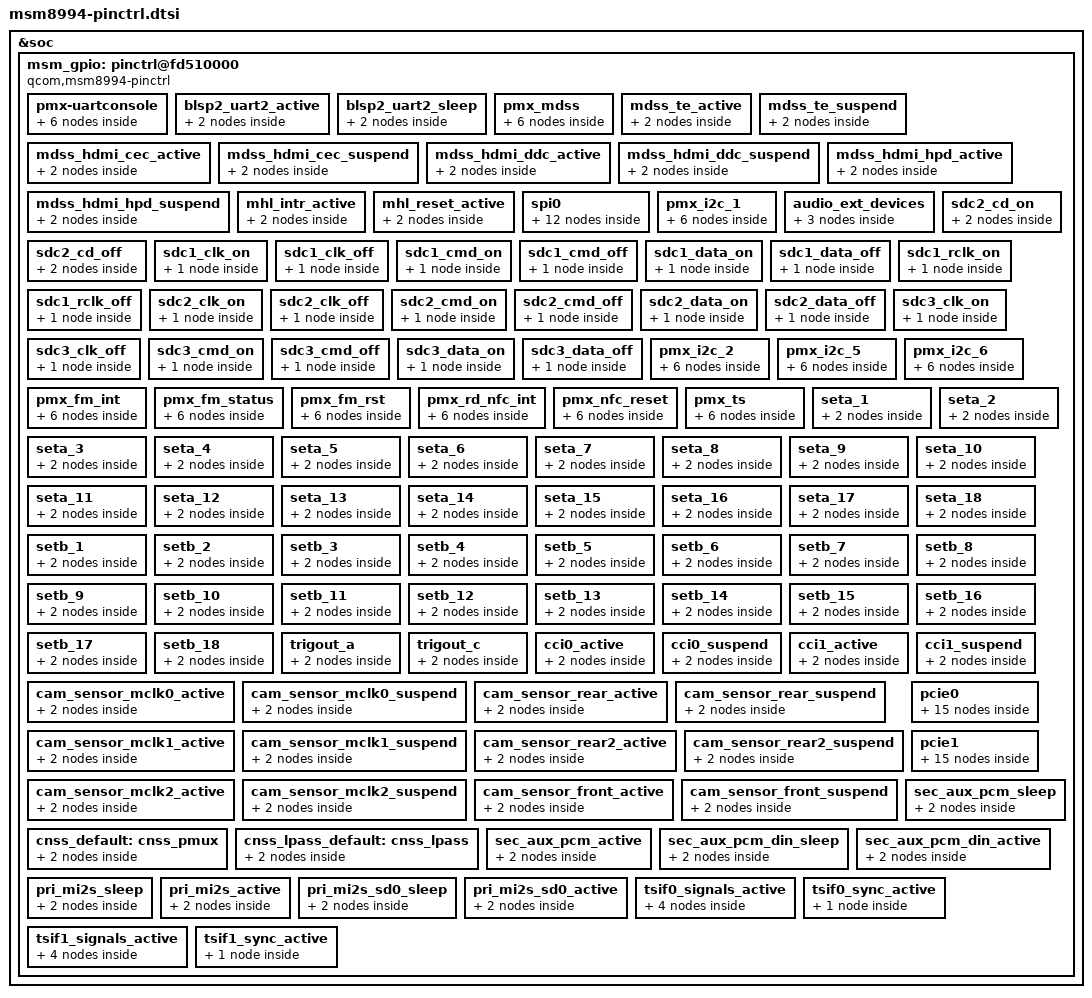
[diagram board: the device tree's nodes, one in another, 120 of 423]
/* Copyright (c) 2013-2015, The Linux Foundation. All rights reserved.
 * Copyright (C) 2016, AngeloGioacchino Del Regno <kholk11@gmail.com>
 *
 * This program is free software; you can redistribute it and/or modify
 * it under the terms of the GNU General Public License version 2 and
 * only version 2 as published by the Free Software Foundation.
 *
 * This program is distributed in the hope that it will be useful,
 * but WITHOUT ANY WARRANTY; without even the implied warranty of
 * MERCHANTABILITY or FITNESS FOR A PARTICULAR PURPOSE.  See the
 * GNU General Public License for more details.
 */

&soc {
	msm_gpio: pinctrl@fd510000 {
		compatible = "qcom,msm8994-pinctrl";
		reg = <0xfd510000 0x4000>;
		interrupts = <0 208 0>;
		gpio-controller;
		#gpio-cells = <2>;
		interrupt-controller;
		#interrupt-cells = <2>;

		pmx-uartconsole {
			uart_console_active: uart_console_active {
				mux {
					pins = "gpio4", "gpio5";
					function = "blsp_uart2";
				};

				config {
					pins = "gpio4", "gpio5";
					drive-strength = <2>;
					bias-disable;
				};
			};

			uart_console_sleep: uart_console_sleep {
				mux {
					pins = "gpio4", "gpio5";
					function = "blsp_uart2";
				};

				config {
					pins = "gpio4", "gpio5";
					drive-strength = <2>;
					bias-pull-down;
				};
			};
		};

		blsp2_uart2_active: blsp2_uart2_active {
			mux {
				pins = "gpio45", "gpio46", "gpio47", "gpio48";
				function = "blsp_uart8";
			};

			config {
				pins = "gpio45", "gpio46", "gpio47", "gpio48";
				drive-strength = <16>;
				bias-disable;
			};
		};

		blsp2_uart2_sleep: blsp2_uart2_sleep {
			mux {
				pins = "gpio45", "gpio46", "gpio47", "gpio48";
				function = "gpio";
			};

			config {
				pins = "gpio45", "gpio46", "gpio47", "gpio48";
				drive-strength = <2>;
				bias-disable;
			};
		};

		pmx_mdss: pmx_mdss {
			mdss_dsi_active: mdss_dsi_active {
				mux {
					pins = "gpio78";
					function = "gpio";
				};

				config {
					pins = "gpio78";
					drive-strength = <8>; /* 8 mA */
					bias-disable = <0>; /* no pull */
				};
			};
			mdss_dsi_suspend: mdss_dsi_suspend {
				mux {
					pins = "gpio78";
					function = "gpio";
				};

				config {
					pins = "gpio78";
					drive-strength = <2>; /* 2 mA */
					bias-pull-down; /* pull down */
				};
			};
		};

		mdss_te_active: mdss_te_active {
			mux {
				pins = "gpio10";
				function = "mdp_vsync";
			};
			config {
				pins = "gpio10";
				drive-strength = <2>; /* 8 mA */
				bias-pull-down; /* pull down*/
			};
		};


		mdss_te_suspend: mdss_te_suspend {
			mux {
				pins = "gpio10";
				function = "mdp_vsync";
			};
			config {
				pins = "gpio10";
				drive-strength = <2>; /* 2 mA */
				bias-pull-down; /* pull down */
			};
		};

		mdss_hdmi_cec_active: mdss_hdmi_cec_active {
			mux {
				pins = "gpio31";
				function = "hdmi_cec";
			};

			config {
				pins = "gpio31";
				drive-strength = <2>;
				bias-pull-up;
			};
		};

		mdss_hdmi_cec_suspend: mdss_hdmi_cec_suspend {
			mux {
				pins = "gpio31";
				function = "hdmi_cec";
			};

			config {
				pins = "gpio31";
				drive-strength = <2>;
				bias-pull-up;
			};
		};

		mdss_hdmi_ddc_active: mdss_hdmi_ddc_active {
			mux {
				pins = "gpio32", "gpio33";
				function = "hdmi_ddc";
			};

			config {
				pins = "gpio32", "gpio33";
				drive-strength = <2>;
				bias-pull-up;
			};
		};

		mdss_hdmi_ddc_suspend: mdss_hdmi_ddc_suspend {
			mux {
				pins = "gpio32", "gpio33";
				function = "hdmi_ddc";
			};

			config {
				pins = "gpio32", "gpio33";
				drive-strength = <2>;
				bias-pull-down;
			};
		};

		mdss_hdmi_hpd_active: mdss_hdmi_hpd_active {
			mux {
				pins = "gpio34";
				function = "hdmi_hpd";
			};

			config {
				pins = "gpio34";
				bias-pull-down;
				drive-strength = <16>;
			};
		};

		mdss_hdmi_hpd_suspend: mdss_hdmi_hpd_suspend {
			mux {
				pins = "gpio34";
				function = "hdmi_hpd";
			};

			config {
				pins = "gpio34";
				bias-pull-down;
				drive-strength = <2>;
			};
		};

		mhl_intr_active: mhl_intr_active {
			mux {
				pins = "gpio57";
				function = "gpio";
			};

			config {
				pins = "gpio57";
				bias-pull-up;
				input-enable;
			};
		};

		mhl_reset_active: mhl_reset_active {
			mux {
				pins = "gpio58";
				function = "gpio";
			};

			config {
				pins = "gpio58";
				drive-strength = <2>;
				bias-pull-down;
				output-low;
			};
		};

		spi0 {

			spi0_default: spi0_default {
				/* active state */
				mux {
					/* MOSI, MISO, CLK */
					pins = "gpio0", "gpio1", "gpio3";
					function = "blsp_spi1";
				};

				config {
					pins = "gpio0", "gpio1", "gpio3";
					drive-strength = <12>; /* 12 MA */
					bias-disable = <0>; /* No PULL */
				};
			};


			spi0_sleep: spi0_sleep {
				/* suspended state */
				mux {
					/* MOSI, MISO, CLK */
					pins = "gpio0", "gpio1", "gpio3";
					function = "gpio";
				};

				config {
					pins = "gpio0", "gpio1", "gpio3";
					drive-strength = <2>; /* 2 MA */
					bias-pull-down; /* PULL Down */
				};
			};

			spi0_cs1_active: cs1_active {
				/* CS */
				mux {
					pins = "gpio8";
					function = "blsp_spi1_cs1";
				};

				config {
					pins = "gpio8";
					drive-strength = <2>;
					bias-disable = <0>;
				};
			};

			spi0_cs1_sleep: cs1_sleep {
				/* CS */
				mux {
					pins = "gpio8";
					function = "gpio";
				};

				config {
					pins = "gpio8";
					drive-strength = <2>;
					bias-disable = <0>;
				};
			};
		};

		pmx_i2c_1 {
			/* active state */
			i2c_1_active: i2c_1_active{
				mux {
					/* CLK, DATA */
					pins = "gpio2", "gpio3";
					function = "blsp_i2c1";
				};

				config {
					pins = "gpio2", "gpio3";
					drive-strength = <2>; /* 2 MA */
					bias-disable; /* No PULL */
				};
			};

			/* suspended state */
			i2c_1_sleep: i2c_1_sleep {
				mux {
					/* CLK, DATA */
					pins = "gpio2", "gpio3";
					function = "blsp_i2c2";
				};

				config {
					pins = "gpio2", "gpio3";
					drive-strength = <2>; /* 2 MA */
					bias-disable; /* No PULL */
				};
			};
		};

		audio_ext_devices {
			/* default state */
			audio_ext_speakers: audio_ext_speakers {
				mux {
					pins = "gpio96";
					function="gpio";
				};

				config {
					pins = "gpio96";
					drive-strength = <2>;
					bias-pull-up;
				};
			};
		};

		sdc2_cd_on: sdc2_cd_on {
			mux {
				pins = "gpio38";
				function = "gpio";
			};

			config {
				pins = "gpio38";
				bias-pull-up;		/* pull up */
				drive-strength = <2>;	/* 2 MA */
			};
		};

		sdc2_cd_off: sdc2_cd_off {
			mux {
				pins = "gpio38";
				function = "gpio";
			};

			config {
				pins = "gpio38";
				bias-pull-up;		/* pull up */
				drive-strength = <2>;	/* 2 MA */
			};
		};

		sdc1_clk_on: sdc1_clk_on {
			config {
				pins = "sdc1_clk";
				bias-disable;		/* NO pull */
				drive-strength = <16>;	/* 16 MA */
			};
		};

		sdc1_clk_off: sdc1_clk_off {
			config {
				pins = "sdc1_clk";
				bias-disable;		/* NO pull */
				drive-strength = <2>;	/* 2 MA */
			};
		};

		sdc1_cmd_on: sdc1_cmd_on {
			config {
				pins = "sdc1_cmd";
				bias-pull-up;		/* pull up */
				drive-strength = <10>;	/* 10 MA */
			};
		};

		sdc1_cmd_off: sdc1_cmd_off {
			config {
				pins = "sdc1_cmd";
				num-grp-pins = <1>;
				bias-pull-up;		/* pull up */
				drive-strength = <2>;	/* 2 MA */
			};
		};

		sdc1_data_on: sdc1_data_on {
			config {
				pins = "sdc1_data";
				bias-pull-up;		/* pull up */
				drive-strength = <10>;	/* 10 MA */
			};
		};

		sdc1_data_off: sdc1_data_off {
			config {
				pins = "sdc1_data";
				bias-pull-up;		/* pull up */
				drive-strength = <2>;	/* 2 MA */
			};
		};

		sdc1_rclk_on: sdc1_rclk_on {
			config {
				pins = "sdc1_rclk";
				bias-pull-down;		/* pull down */
			};
		};

		sdc1_rclk_off: sdc1_rclk_off {
			config {
				pins = "sdc1_rclk";
				bias-pull-down;		/* pull down */
			};
		};

		sdc2_clk_on: sdc2_clk_on {
			config {
				pins = "sdc2_clk";
				bias-disable;		/* NO pull */
				drive-strength = <16>;	/* 16 MA */
			};
		};

		sdc2_clk_off: sdc2_clk_off {
			config {
				pins = "sdc2_clk";
				bias-disable;		/* NO pull */
				drive-strength = <2>;	/* 2 MA */
			};
		};

		sdc2_cmd_on: sdc2_cmd_on {
			config {
				pins = "sdc2_cmd";
				bias-pull-up;		/* pull up */
				drive-strength = <10>;	/* 10 MA */
			};
		};

		sdc2_cmd_off: sdc2_cmd_off {
			config {
				pins = "sdc2_cmd";
				bias-pull-up;		/* pull up */
				drive-strength = <2>;	/* 2 MA */
			};
		};

		sdc2_data_on: sdc2_data_on {
			config {
				pins = "sdc2_data";
				bias-pull-up;		/* pull up */
				drive-strength = <10>;	/* 10 MA */
			};
		};

		sdc2_data_off: sdc2_data_off {
			config {
				pins = "sdc2_data";
				bias-pull-up;		/* pull up */
				drive-strength = <2>;	/* 2 MA */
			};
		};

		sdc3_clk_on: sdc3_clk_on {
			config {
				pins = "sdc3_clk";
				bias-disable;		/* NO pull */
				drive-strength = <16>;	/* 16 MA */
			};
		};

		sdc3_clk_off: sdc3_clk_off {
			config {
				pins = "sdc3_clk";
				bias-disable;		/* NO pull */
				drive-strength = <2>;	/* 2 MA */
			};
		};

		sdc3_cmd_on: sdc3_cmd_on {
			config {
				pins = "sdc3_cmd";
				bias-pull-up;		/* pull up */
				drive-strength = <10>;	/* 10 MA */
			};
		};

		sdc3_cmd_off: sdc3_cmd_off {
			config {
				pins = "sdc3_cmd";
				bias-pull-up;		/* pull up */
				drive-strength = <2>;	/* 2 MA */
			};
		};

		sdc3_data_on: sdc3_data_on {
			config {
				pins = "sdc3_data";
				bias-pull-up;		/* pull up */
				drive-strength = <10>;	/* 10 MA */
			};
		};

		sdc3_data_off: sdc3_data_off {
			config {
				pins = "sdc3_data";
				bias-pull-up;		/* pull up */
				drive-strength = <2>;	/* 2 MA */
			};
		};

		pmx_i2c_2 {
			/* active state */
			i2c_2_active: i2c_2_active{
				mux {
					/* CLK, DATA */
					pins = "gpio6", "gpio7";
					function = "blsp_i2c2";
				};

				config {
					pins = "gpio6", "gpio7";
					drive-strength = <2>; /* 2 MA */
					bias-disable; /* No PULL */
				};
			};

			/* suspended state */
			i2c_2_sleep: i2c_2_sleep {
				mux {
					/* CLK, DATA */
					pins = "gpio6", "gpio7";
					function = "blsp_i2c2";
				};

				config {
					pins = "gpio6", "gpio7";
					drive-strength = <2>; /* 2 MA */
					bias-disable; /* No PULL */
				};
			};
		};

		pmx_i2c_5 {
			/* active state */
			i2c_5_active: i2c_5_active{
				mux {
					/* CLK, DATA */
					pins = "gpio83", "gpio84";
					function = "blsp_i2c5";
				};

				config {
					pins = "gpio83", "gpio84";
					drive-strength = <2>; /* 2 MA */
					bias-disable; /* No PULL */
				};
			};

			/* suspended state */
			i2c_5_sleep: i2c_5_sleep {
				mux {
					/* CLK, DATA */
					pins = "gpio83", "gpio84";
					function = "blsp_i2c5";
				};

				config {
					pins = "gpio83", "gpio84";
					drive-strength = <2>; /* 2 MA */
					bias-disable; /* No PULL */
				};
			};
		};

		pmx_i2c_6 {
			i2c_6_active: i2c_6_active {
				mux {
					pins = "gpio27", "gpio28";
					function = "blsp_i2c6";
				};

				config {
					pins = "gpio27", "gpio28";
					drive-strength = <2>;
					bias-disable;
				};
			};

			i2c_6_sleep: i2c_6_sleep {
				mux {
					pins = "gpio27", "gpio28";
					function = "blsp_i2c6";
				};

				config {
					pins = "gpio27", "gpio28";
					drive-strength = <2>;
					bias-pull-up;
				};
			};
		};

		pmx_fm_int {
			fm_int_active: fm_int_active {
				mux {
					pins = "gpio9";
					function = "gpio";
				};

				config {
					pins = "gpio9";
					drive-strength = <16>;
					bias-pull-up;
				};
			};

		fm_int_suspend: fm_int_suspend {
				mux {
					pins = "gpio9";
					function = "gpio";
				};

				config {
					pins = "gpio9";
					drive-strength = <16>;
					bias-pull-up;
				};
			};
		};

		pmx_fm_status {
			fm_status_int_active: fm_status_int_active {
				mux {
					pins = "gpio11";
					function = "gpio";
				};

				config {
					pins = "gpio11";
					drive-strength = <16>;
					bias-pull-up;
				};
			};

			fm_status_int_suspend: fm_status_int_suspend {
				mux {
					pins = "gpio11";
					function = "gpio";
				};

				config {
					pins = "gpio11";
					drive-strength = <16>;
					bias-pull-up;
				};
			};
		};

		pmx_fm_rst {
			fm_rst_active: fm_rst_active {
				mux {
					pins = "gpio62";
					function = "gpio";
				};

				config {
					pins = "gpio62";
					drive-strength = <16>;
					bias-pull-down;
				};
			};

			fm_rst_suspend: fm_rst_suspend {
				mux {
					pins = "gpio62";
					function = "gpio";
				};

				config {
					pins = "gpio62";
					drive-strength = <16>;
					bias-pull-down;
				};
			};
		};

		pmx_rd_nfc_int {
			nfc_int_active: active {
				mux {
					pins = "gpio29";
					function = "gpio";
				};

				config {
					pins = "gpio29";
					drive-strength = <6>;
					bias-pull-up;
				};
			};

			nfc_int_suspend: suspend {
				mux {
					pins = "gpio29";
					function = "gpio";
				};

				config {
					pins = "gpio29";
					drive-strength = <6>;
					bias-pull-up;
				};
			};
		};

		pmx_nfc_reset {
			nfc_disable_active: active {
				mux {
					pins = "gpio30";
					function = "gpio";
				};

				config {
					pins = "gpio30";
					drive-strength = <6>;
					bias-pull-up;
				};
			};

			nfc_disable_suspend: suspend {
				mux {
					pins = "gpio30";
					function = "gpio";
				};

				config {
					pins = "gpio30";
					drive-strength = <6>;
					bias-disable;
				};
			};
		};

		pmx_ts {
			ts_active: ts_active {
				mux {
					pins = "gpio60", "gpio61";
					function = "gpio";
				};

				config {
					pins = "gpio60", "gpio61";
					drive-strength = <16>;
					bias-pull-up;
				};
			};

			ts_suspend: ts_suspend {
				mux {
					pins = "gpio60", "gpio61";
					function = "gpio";
				};

				config {
					pins = "gpio60", "gpio61";
					drive-strength = <16>;
					bias-disable;
				};
			};
		};

		/* CoreSight */
		seta_1: seta_1 {
			mux {
				pins = "gpio27";
				function = "gpio";
			};

			config {
				pins = "gpio27";
				function = "qdss_tracectl_a";
				drive-strength = <16>;
				bias-disable;
			};
		};

		seta_2: seta_2 {
			mux {
				pins = "gpio28";
				function = "qdss_tracectl_a";
			};

			config {
				pins = "gpio28";
				drive-strength = <16>;
				bias-disable;
			};
		};

		seta_3: seta_3 {
			mux {
				pins = "gpio53";
				function = "qdss_tracedata_a";
			};

			config {
				pins = "gpio53";
				drive-strength = <16>;
				bias-disable;
			};
		};

		seta_4: seta_4 {
			mux {
				pins = "gpio54";
				function = "qdss_tracedata_a";
			};

			config {
				pins = "gpio54";
				drive-strength = <16>;
				bias-disable;
			};
		};

		seta_5: seta_5 {
			mux {
				pins = "gpio63";
				function = "qdss_tracedata_a";
			};

			config {
				pins = "gpio63";
				drive-strength = <16>;
				bias-disable;
			};
		};

		seta_6: seta_6 {
			mux {
				pins = "gpio64";
				function = "qdss_tracedata_a";
			};

			config {
				pins = "gpio64";
				drive-strength = <16>;
				bias-disable;
			};
		};

		seta_7: seta_7 {
			mux {
				pins = "gpio65";
				function = "qdss_tracedata_a";
			};

			config {
				pins = "gpio65";
				drive-strength = <16>;
				bias-disable;
			};
		};

		seta_8: seta_8 {
			mux {
				pins = "gpio66";
				function = "qdss_tracedata_a";
			};

			config {
				pins = "gpio66";
				drive-strength = <16>;
				bias-disable;
			};
		};

		seta_9: seta_9 {
			mux {
				pins = "gpio67";
				function = "qdss_tracedata_a";
			};

			config {
				pins = "gpio67";
				drive-strength = <16>;
				bias-disable;
			};
		};

		seta_10: seta_10 {
			mux {
				pins = "gpio74";
				function = "qdss_tracedata_a";
			};

			config {
				pins = "gpio74";
				drive-strength = <16>;
				bias-disable;
			};
		};

		seta_11: seta_11 {
			mux {
				pins = "gpio75";
				function = "qdss_tracedata_a";
			};

			config {
				pins = "gpio75";
				drive-strength = <16>;
				bias-disable;
			};
		};

		seta_12: seta_12 {
			mux {
				pins = "gpio76";
				function = "qdss_tracedata_a";
			};

			config {
				pins = "gpio76";
				drive-strength = <16>;
				bias-disable;
			};
		};

		seta_13: seta_13 {
			mux {
				pins = "gpio77";
				function = "qdss_tracedata_a";
			};

			config {
				pins = "gpio77";
				drive-strength = <16>;
				bias-disable;
			};
		};

		seta_14: seta_14 {
			mux {
				pins = "gpio85";
				function = "qdss_tracedata_a";
			};

			config {
				pins = "gpio85";
				drive-strength = <16>;
				bias-disable;
			};
		};

		seta_15: seta_15 {
			mux {
				pins = "gpio86";
				function = "qdss_tracedata_a";
			};

			config {
				pins = "gpio86";
				drive-strength = <16>;
				bias-disable;
			};
		};

		seta_16: seta_16 {
			mux {
				pins = "gpio87";
				function = "qdss_tracedata_a";
			};

			config {
				pins = "gpio87";
				drive-strength = <16>;
				bias-disable;
			};
		};

		seta_17: seta_17 {
			mux {
				pins = "gpio89";
				function = "qdss_tracedata_a";
			};

			config {
				pins = "gpio89";
				drive-strength = <16>;
				bias-disable;
			};
		};

		seta_18: seta_18 {
			mux {
				pins = "gpio90";
				function = "qdss_tracedata_a";
			};

			config {
				pins = "gpio90";
				drive-strength = <16>;
				bias-disable;
			};
		};

		setb_1: setb_1 {
			mux {
				pins = "gpio13";
				function = "qdss_tracedata_b";
			};

			config {
				pins = "gpio13";
				drive-strength = <16>;
				bias-disable;
			};
		};

		setb_2: setb_2 {
			mux {
				pins = "gpio14";
				function = "qdss_tracedata_b";
			};

			config {
				pins = "gpio14";
				drive-strength = <16>;
				bias-disable;
			};
		};

		setb_3: setb_3 {
			mux {
				pins = "gpio15";
				function = "qdss_tracedata_b";
			};

			config {
				pins = "gpio15";
				drive-strength = <16>;
				bias-disable;
			};
		};

		setb_4: setb_4 {
			mux {
				pins = "gpio16";
				function = "qdss_tracedata_b";
			};

			config {
				pins = "gpio16";
				drive-strength = <16>;
				bias-disable;
			};
		};

		setb_5: setb_5 {
			mux {
				pins = "gpio17";
				function = "qdss_tracedata_b";
			};

			config {
				pins = "gpio17";
				drive-strength = <16>;
				bias-disable;
			};
		};

		setb_6: setb_6 {
			mux {
				pins = "gpio18";
				function = "qdss_tracedata_b";
			};

			config {
				pins = "gpio18";
				drive-strength = <16>;
				bias-disable;
			};
		};

		setb_7: setb_7 {
			mux {
				pins = "gpio19";
				function = "qdss_tracedata_b";
			};

			config {
				pins = "gpio19";
				drive-strength = <16>;
				bias-disable;
			};
		};

		setb_8: setb_8 {
			mux {
				pins = "gpio21";
				function = "qdss_tracedata_b";
			};

			config {
				pins = "gpio21";
				drive-strength = <16>;
				bias-disable;
			};
		};

		setb_9: setb_9 {
			mux {
				pins = "gpio22";
				function = "qdss_tracedata_b";
			};

			config {
				pins = "gpio22";
				drive-strength = <16>;
				bias-disable;
			};
		};

		setb_10: setb_10 {
			mux {
				pins = "gpio23";
				function = "qdss_tracedata_b";
			};

			config {
				pins = "gpio23";
				drive-strength = <16>;
				bias-disable;
			};
		};

		setb_11: setb_11 {
			mux {
				pins = "gpio25";
				function = "qdss_tracedata_b";
			};

			config {
				pins = "gpio25";
				drive-strength = <16>;
				bias-disable;
			};
		};
		setb_12: setb_12 {
			mux {
				pins = "gpio26";
				function = "qdss_tracedata_b";
			};

			config {
				pins = "gpio26";
				drive-strength = <16>;
				bias-disable;
			};
		};

		setb_13: setb_13 {
			mux {
				pins = "gpio57";
				function = "qdss_tracedata_b";
			};

			config {
				pins = "gpio57";
				drive-strength = <16>;
				bias-disable;
			};
		};

		setb_14: setb_14 {
			mux {
				pins = "gpio58";
				function = "qdss_tracedata_b";
			};

			config {
				pins = "gpio58";
				drive-strength = <16>;
				bias-disable;
			};
		};

		setb_15: setb_15 {
			mux {
				pins = "gpio91";
				function = "qdss_traceclk_b";
			};

			config {
				pins = "gpio91";
				drive-strength = <16>;
				bias-disable;
			};
		};

		setb_16: setb_16 {
			mux {
				pins = "gpio92";
				function = "qdss_tracedata_b";
			};

			config {
				pins = "gpio92";
				drive-strength = <16>;
				bias-disable;
			};
		};

		setb_17: setb_17 {
			mux {
				pins = "gpio93";
				function = "qdss_tracedata_b";
			};

			config {
				pins = "gpio93";
				drive-strength = <16>;
				bias-disable;
			};
		};

		setb_18: setb_18 {
			mux {
				pins = "gpio94";
				function = "qdss_tracectl_b";
			};

			config {
				pins = "gpio94";
				drive-strength = <16>;
				bias-disable;
			};
		};

		trigout_a: trigout_a {
			mux {
				pins = "gpio56";
				function = "qdss_cti_trig_out_a";
			};

			config {
				pins = "gpio56";
				drive-strength = <2>;
				bias-disable;
			};
		};

		trigout_c: trigout_c {
			mux {
				pins = "gpio41";
				function = "qdss_cti_trig_out_a";
			};

			config {
				pins = "gpio41";
				drive-strength = <2>;
				bias-disable;
			};
		};

		cci0_active: cci0_active {
			mux {
				/* CLK, DATA */
				pins = "gpio17","gpio18"; // Only 2
				function = "cci_i2c";
			};

			config {
				pins = "gpio17","gpio18";
				bias-pull-up; /* PULL UP*/
				drive-strength = <2>; /* 2 MA */
			};
		};

		cci0_suspend: cci0_suspend {
			mux {
				/* CLK, DATA */
				pins = "gpio17","gpio18";
				function = "cci_i2c";
			};

			config {
				pins = "gpio17","gpio18";
				bias-pull-down; /* PULL DOWN */
				drive-strength = <2>; /* 2 MA */
			};
		};

		cci1_active: cci1_active {
			mux {
				/* CLK, DATA */
				pins = "gpio19","gpio20";
				function = "cci_i2c";
			};

			config {
				pins = "gpio19","gpio20";
				bias-pull-up; /* PULL UP*/
				drive-strength = <2>; /* 2 MA */
			};
		};

		cci1_suspend: cci1_suspend {
			mux {
				/* CLK, DATA */
				pins = "gpio19","gpio20";
				function = "cci_i2c";
			};

			config {
				pins = "gpio19","gpio20";
				bias-pull-down; /* PULL DOWN */
				drive-strength = <2>; /* 2 MA */
			};
		};

		cam_sensor_mclk0_active: cam_sensor_mclk0_active {
			/* MCLK0 */
			mux {
				/* CLK, DATA */
				pins = "gpio13";
				function = "cam_mclk";
			};

			config {
				pins = "gpio13";
				bias-disable; /* No PULL */
				drive-strength = <2>; /* 2 MA */
			};
		};

		cam_sensor_mclk0_suspend: cam_sensor_mclk0_suspend {
			/* MCLK0 */
			mux {
				/* CLK, DATA */
				pins = "gpio13";
				function = "cam_mclk";
			};

			config {
				pins = "gpio13";
				bias-pull-down; /* PULL DOWN */
				drive-strength = <2>; /* 2 MA */
			};
		};

		cam_sensor_rear_active: cam_sensor_rear_active {
			/* RESET, STANDBY */
			mux {
				pins = "gpio92";
				function = "gpio";
			};

			config {
				pins = "gpio92", "gpio91";
				bias-disable; /* No PULL */
				drive-strength = <2>; /* 2 MA */
			};
		};

		cam_sensor_rear_suspend: cam_sensor_rear_suspend{
			/* RESET, STANDBY */
			mux {
				pins = "gpio92", "gpio91";
				function = "gpio";
			};

			config {
				pins = "gpio92", "gpio91";
				bias-disable; /* No PULL */
				drive-strength = <2>; /* 2 MA */
			};
		};

		cam_sensor_mclk1_active: cam_sensor_mclk1_active{
			/* MCLK1 */
			mux {
				/* CLK, DATA */
				pins = "gpio14";
				function = "cam_mclk";
			};

			config {
				pins = "gpio14";
				bias-disable; /* No PULL */
				drive-strength = <2>; /* 2 MA */
			};
		};

		cam_sensor_mclk1_suspend: cam_sensor_mclk1_suspend {
			/* MCLK1 */
			mux {
				/* CLK, DATA */
				pins = "gpio14";
				function = "cam_mclk";
			};

			config {
				pins = "gpio14";
				bias-pull-down; /* PULL DOWN */
				drive-strength = <2>; /* 2 MA */
			};
		};

		cam_sensor_rear2_active: cam_sensor_rear2_active {
			/* RESET, STANDBY */
			mux {
				pins = "gpio94";
				function = "gpio";
			};

			config {
				pins = "gpio94", "gpio93";
				bias-disable; /* No PULL */
				drive-strength = <2>; /* 2 MA */
			};
		};

		cam_sensor_rear2_suspend: cam_sensor_rear2_suspend{
			/* RESET, STANDBY */
			mux {
				pins = "gpio94", "gpio93";
				function = "gpio";
			};

			config {
				pins = "gpio94", "gpio93";
				bias-disable; /* No PULL */
				drive-strength = <2>; /* 2 MA */
			};
		};

		cam_sensor_mclk2_active: cam_sensor_mclk2_active {
			/* MCLK2 */
			mux {
				/* CLK, DATA */
				pins = "gpio15";
				function = "cam_mclk";
			};

			config {
				pins = "gpio15";
				bias-disable; /* No PULL */
				drive-strength = <2>; /* 2 MA */
			};
		};

		cam_sensor_mclk2_suspend: cam_sensor_mclk2_suspend{
			/* MCLK2 */
			mux {
				/* CLK, DATA */
				pins = "gpio15";
				function = "cam_mclk";
			};

			config {
				pins = "gpio15";
				bias-pull-down; /* PULL DOWN */
				drive-strength = <2>; /* 2 MA */
			};
		};

		cam_sensor_front_active: cam_sensor_front_active{
			/* RESET, STANDBY */
			mux {
				pins = "gpio104", "gpio105";
				function = "gpio";
			};

			config {
				pins = "gpio104","gpio105";
				bias-disable; /* No PULL */
				drive-strength = <2>; /* 2 MA */
			};
		};

		cam_sensor_front_suspend: cam_sensor_front_suspend{
			/* RESET, STANDBY */
			mux {
				pins = "gpio104", "gpio105";
				function = "gpio";
			};

			config {
				pins = "gpio104","gpio105";
				bias-disable; /* No PULL */
				drive-strength = <2>; /* 2 MA */
			};
		};


		cnss_default: cnss_pmux {
			/* MCLK2 */
			mux {
				/* CLK, DATA */
				pins = "gpio113";
				function = "gpio";
			};

			config {
				pins = "gpio113";
				bias-pull-down; /* PULL DOWN */
				drive-strength = <16>; /* 16 MA */
			};
		};

		cnss_lpass_default: cnss_lpass {
			mux {
				pins = "gpio112";
				function = "gpio";
			};

			config {
				pins = "gpio112";
				drive-strength = <16>;
				bias-pull-down;
			};
		};

		pcie0 {
			pcie0_clkreq_default: pcie0_clkreq_default {
				mux {
					pins = "gpio54";
					function = "pci_e0";
				};

				config {
					pins = "gpio54";
					drive-strength = <2>;
					bias-pull-up;
				};
			};

			pcie0_perst_default: pcie0_perst_default {
				mux {
					pins = "gpio53";
					function = "gpio";
				};

				config {
					pins = "gpio53";
					drive-strength = <2>;
					bias-pull-down;
				};
			};

			pcie0_wake_default: pcie0_wake_default {
				mux {
					pins = "gpio55";
					function = "gpio";
				};

				config {
					pins = "gpio55";
					drive-strength = <2>;
					bias-pull-down;
				};
			};

			pcie0_clkreq_sleep: pcie0_clkreq_sleep {
				mux {
					pins = "gpio54";
					function = "gpio";
				};

				config {
					pins = "gpio54";
					drive-strength = <2>;
					bias-disable;
				};
			};

			pcie0_wake_sleep: pcie0_wake_sleep {
				mux {
					pins = "gpio55";
					function = "gpio";
				};

				config {
					pins = "gpio55";
					drive-strength = <2>;
					bias-disable;
				};
			};
		};

		pcie1 {
			pcie1_clkreq_default: pcie1_clkreq_default {
				mux {
					pins = "gpio36";
					function = "pci_e1";
				};

				config {
					pins = "gpio36";
					drive-strength = <2>;
					bias-pull-up;
				};
			};

			pcie1_perst_default: pcie1_perst_default {
				mux {
					pins = "gpio35";
					function = "gpio";
				};

				config {
					pins = "gpio35";
					drive-strength = <2>;
					bias-pull-down;
				};
			};

			pcie1_wake_default: pcie1_wake_default {
				mux {
					pins = "gpio37";
					function = "gpio";
				};

				config {
					pins = "gpio37";
					drive-strength = <2>;
					bias-pull-down;
				};
			};

			pcie1_clkreq_sleep: pcie1_clkreq_sleep {
				mux {
					pins = "gpio36";
					function = "gpio";
				};

				config {
					pins = "gpio36";
					drive-strength = <2>;
					bias-disable;
				};
			};

			pcie1_wake_sleep: pcie1_wake_sleep {
				mux {
					pins = "gpio37";
					function = "gpio";
				};

				config {
					pins = "gpio37";
					drive-strength = <2>;
					bias-disable;
				};
			};
		};

		sec_aux_pcm_sleep: sec_aux_pcm_sleep {
			mux {
				pins = "gpio79", "gpio80", "gpio82";
				function = "sec_mi2s";
			};

			config {
				pins = "gpio79", "gpio80", "gpio82";
				drive-strength = <2>;	/* 2 mA */
				bias-pull-down;		/* PULL DOWN */
				input-enable;
			};
		};

		sec_aux_pcm_active: sec_aux_pcm_active {
			mux {
				pins = "gpio79", "gpio80", "gpio82";
				function = "sec_mi2s";
			};

			config {
				pins = "gpio79", "gpio80", "gpio82";
				drive-strength = <8>;	/* 8 mA */
				bias-disable;		/* NO PULL */
				output-high;
			};
		};

		sec_aux_pcm_din_sleep: sec_aux_pcm_din_sleep {
			mux {
				pins = "gpio81";
				function = "sec_mi2s";
			};

			config {
				pins = "gpio81";
				drive-strength = <2>;	/* 2 mA */
				bias-pull-down;		/* PULL DOWN */
				input-enable;
			};
		};

		sec_aux_pcm_din_active: sec_aux_pcm_din_active {
			mux {
				pins = "gpio81";
				function = "sec_mi2s";
			};

			config {
				drive-strength = <8>;	/* 8 mA */
				bias-disable;		/* NO PULL */
			};
		};

		pri_mi2s_sleep: pri_mi2s_sleep {
			mux {
				pins = "gpio65", "gpio66";
				function = "pri_mi2s";
			};

			config {
				pins = "gpio65", "gpio66";
				drive-strength = <2>;	/* 2 mA */
				bias-pull-down;		/* PULL DOWN */
				input-enable;
			};
		};

		pri_mi2s_active: pri_mi2s_active {
			mux {
				pins = "gpio65", "gpio66";
				function = "pri_mi2s";
			};
			config {
				pins = "gpio65", "gpio66";
				drive-strength = <2>;	/* 2 mA */
				bias-disable;		/* NO PULL */
				output-high;
			};
		};

		pri_mi2s_sd0_sleep: pri_mi2s_sd0_sleep {
			mux {
				pins = "gpio67";
				function = "pri_mi2s";
			};

			config {
				pins = "gpio67";
				drive-strength = <2>;	/* 2 mA */
				bias-pull-down;		/* PULL DOWN */
				input-enable;
			};
		};

		pri_mi2s_sd0_active: pri_mi2s_sd0_active {
			mux {
				pins = "gpio67";
				function = "pri_mi2s";
			};

			config {
				pins = "gpio67";
				drive-strength = <2>;	/* 2 mA */
				bias-disable;		/* NO PULL */
			};
		};

		tsif0_signals_active: tsif0_signals_active {
			tsif1_clk {
				pins = "gpio89"; /* TSIF0 CLK */
				function = "tsif1_clk";
			};
			tsif1_en {
				pins = "gpio90"; /* TSIF0 Enable */
				function = "tsif1_en";
			};
			tsif1_data {
				pins = "gpio91"; /* TSIF0 DATA */
				function = "tsif1_data";
			};
			signals_cfg {
				pins = "gpio89", "gpio90", "gpio91";
				drive_strength = <2>;	/* 2 mA */
				bias-pull-down;		/* pull down */
			};
		};

		/* sync signal is only used if configured to mode-2 */
		tsif0_sync_active: tsif0_sync_active {
			tsif1_sync {
				pins = "gpio110";	/* TSIF0 SYNC */
				function = "tsif1_sync";
				drive_strength = <2>;	/* 2 mA */
				bias-pull-down;		/* pull down */
			};
		};

		tsif1_signals_active: tsif1_signals_active {
			tsif2_clk {
				pins = "gpio93"; /* TSIF1 CLK */
				function = "tsif2_clk";
			};
			tsif2_en {
				pins = "gpio94"; /* TSIF1 Enable */
				function = "tsif2_en";
			};
			tsif2_data {
				pins = "gpio95"; /* TSIF1 DATA */
				function = "tsif2_data";
			};
			signals_cfg {
				pins = "gpio93", "gpio94", "gpio95";
				drive_strength = <2>;	/* 2 mA */
				bias-pull-down;		/* pull down */
			};
		};

		/* sync signal is only used if configured to mode-2 */
		tsif1_sync_active: tsif1_sync_active {
			tsif2_sync {
				pins = "gpio96";	/* TSIF1 SYNC */
				function = "tsif2_sync";
				drive_strength = <2>;	/* 2 mA */
				bias-pull-down;		/* pull down */
			};
		};
	};
};
